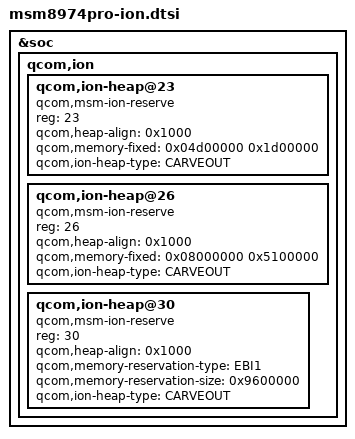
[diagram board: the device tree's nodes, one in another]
/* Copyright (c) 2013, The Linux Foundation. All rights reserved.
 *
 * This program is free software; you can redistribute it and/or modify
 * it under the terms of the GNU General Public License version 2 and
 * only version 2 as published by the Free Software Foundation.
 *
 * This program is distributed in the hope that it will be useful,
 * but WITHOUT ANY WARRANTY; without even the implied warranty of
 * MERCHANTABILITY or FITNESS FOR A PARTICULAR PURPOSE.  See the
 * GNU General Public License for more details.
 */

&soc {
	qcom,ion {
		qcom,ion-heap@23 { /* OTHER PIL HEAP */
			compatible = "qcom,msm-ion-reserve";
			reg = <23>;
			qcom,heap-align = <0x1000>;
			qcom,memory-fixed = <0x04d00000 0x1d00000>;
			qcom,ion-heap-type = "CARVEOUT";
		};

		qcom,ion-heap@26 { /* MODEM HEAP */
			compatible = "qcom,msm-ion-reserve";
			reg = <26>;
			qcom,heap-align = <0x1000>;
			qcom,memory-fixed = <0x08000000 0x5100000>;
			qcom,ion-heap-type = "CARVEOUT";
		};

		qcom,ion-heap@30 { /* CAMERA HEAP */
			compatible = "qcom,msm-ion-reserve";
			reg = <30>;
			qcom,heap-align = <0x1000>;
			qcom,memory-reservation-type = "EBI1"; /* reserve EBI memory */
			qcom,memory-reservation-size = <0x9600000>;
			qcom,ion-heap-type = "CARVEOUT";
		};
	};
};
